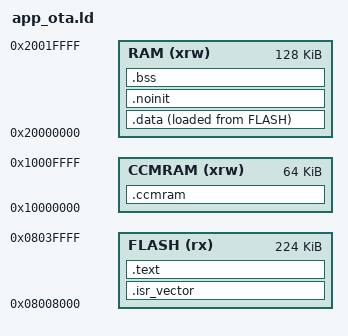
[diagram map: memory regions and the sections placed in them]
ENTRY(Reset_Handler)

MEMORY
{
  FLASH (rx)      : ORIGIN = 0x08008000, LENGTH = 224K
  RAM (xrw)       : ORIGIN = 0x20000000, LENGTH = 128K
  CCMRAM (xrw)    : ORIGIN = 0x10000000, LENGTH = 64K
}

_estack = ORIGIN(RAM) + LENGTH(RAM);

SECTIONS
{
  .isr_vector :
  {
    . = ALIGN(4);
    KEEP(*(.isr_vector))
    . = ALIGN(4);
  } >FLASH

  .text :
  {
    . = ALIGN(4);
    *(.text)
    *(.text*)
    *(.rodata)
    *(.rodata*)
    . = ALIGN(4);
    _etext = .;
  } >FLASH

  _sidata = LOADADDR(.data);

  .data :
  {
    . = ALIGN(4);
    _sdata = .;
    *(.data)
    *(.data*)
    . = ALIGN(4);
    _edata = .;
  } >RAM AT> FLASH

  /* Not zeroed at boot: survives a reset (fault record). Kept before .bss
   * so newlib's heap, which starts at _ebss, never overlaps it. */
  .noinit (NOLOAD) :
  {
    . = ALIGN(4);
    *(.noinit)
    *(.noinit*)
    . = ALIGN(4);
  } >RAM

  .bss :
  {
    . = ALIGN(4);
    _sbss = .;
    *(.bss)
    *(.bss*)
    *(COMMON)
    . = ALIGN(4);
    _ebss = .;
    __bss_end__ = _ebss;
  } >RAM

  PROVIDE ( end = _ebss );
  PROVIDE ( _end = _ebss );

  .ccmram (NOLOAD) :
  {
    . = ALIGN(4);
    _sccmram = .;
    *(.ccmram)
    *(.ccmram*)
    . = ALIGN(4);
    _eccmram = .;
  } >CCMRAM
}
